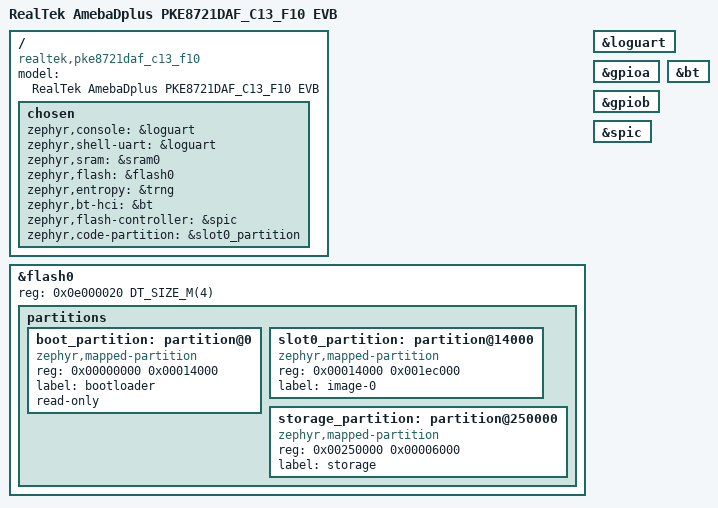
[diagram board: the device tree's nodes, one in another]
/*
 * Copyright (c) 2026 Realtek Semiconductor Corp.
 *
 * SPDX-License-Identifier: Apache-2.0
 */

/dts-v1/;

#include <realtek/amebadplus/amebadplus.dtsi>
#include "pke8721daf_c13_f10-pinctrl.dtsi"

/ {
	compatible = "realtek,pke8721daf_c13_f10";
	model = "RealTek AmebaDplus PKE8721DAF_C13_F10 EVB";

	chosen {
		zephyr,console = &loguart;
		zephyr,shell-uart = &loguart;
		zephyr,sram = &sram0;
		zephyr,flash = &flash0;
		zephyr,entropy = &trng;
		zephyr,bt-hci = &bt;
		zephyr,flash-controller = &spic;
		zephyr,code-partition = &slot0_partition;
	};
};

&flash0 {
	reg = <0x0e000020 DT_SIZE_M(4)>;
	ranges = <0x0 0x0e000020 DT_SIZE_M(4)>;

	partitions {
		ranges;
		#address-cells = <1>;
		#size-cells = <1>;

		boot_partition: partition@0 {
			compatible = "zephyr,mapped-partition";
			reg = <0x00000000 0x00014000>;
			label = "bootloader";
			read-only;
		};

		slot0_partition: partition@14000 {
			compatible = "zephyr,mapped-partition";
			reg = <0x00014000 0x001ec000>;
			label = "image-0";
		};

		storage_partition: partition@250000 {
			compatible = "zephyr,mapped-partition";
			reg = <0x00250000 0x00006000>;
			label = "storage";
		};
	};
};

&loguart {
	status = "okay";
};

&gpioa {
	status = "okay";
};

&gpiob {
	status = "okay";
};

&bt {
	status = "okay";
};

&spic {
	status = "okay";
};
